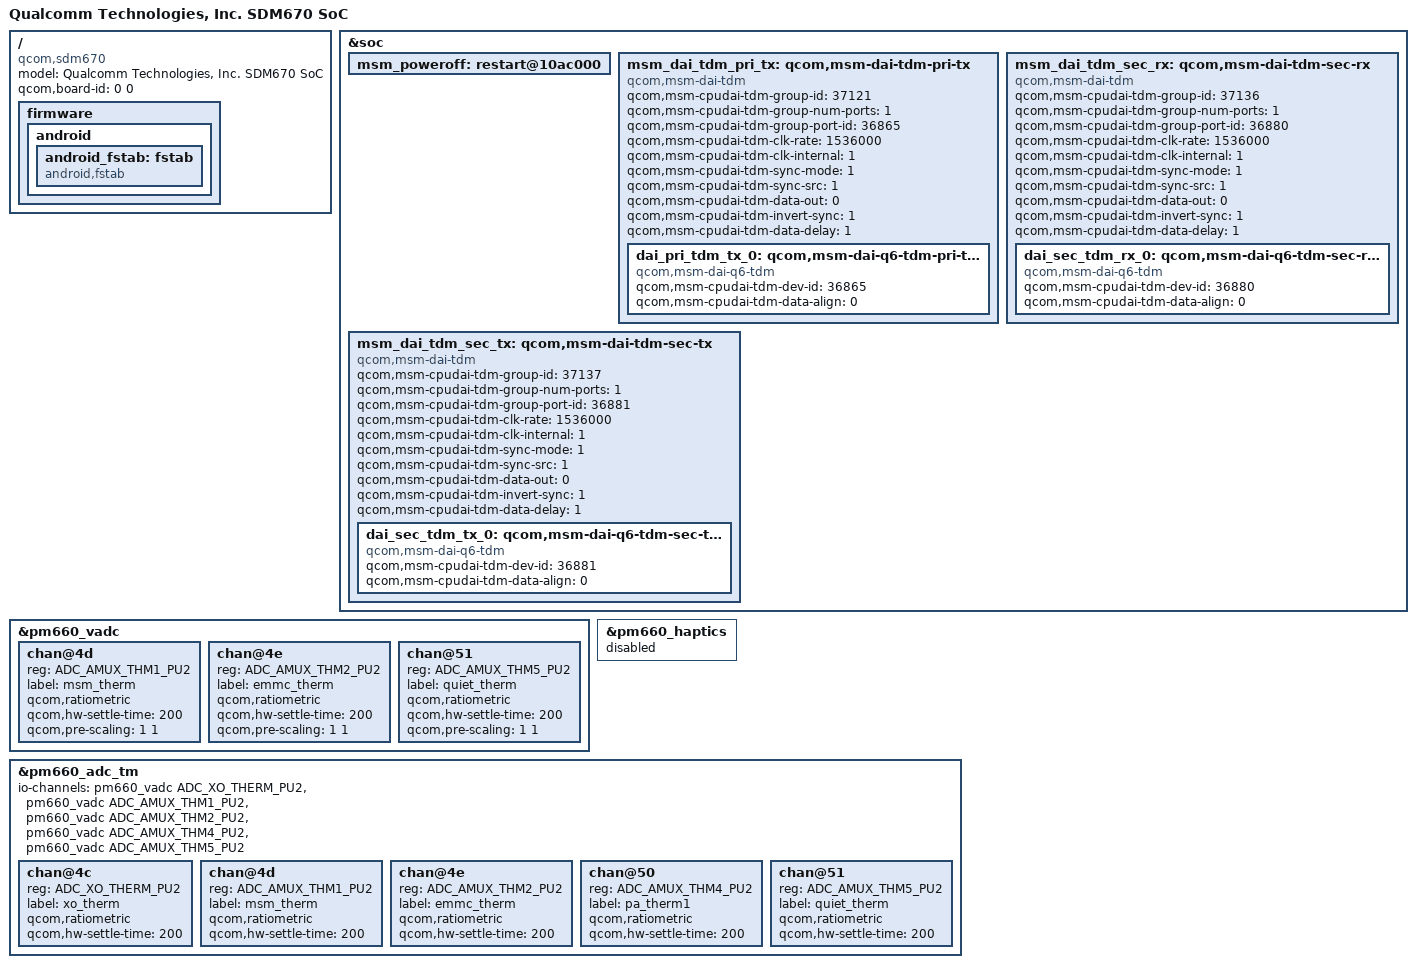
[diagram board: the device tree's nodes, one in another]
// SPDX-License-Identifier: GPL-2.0-only
/*
 * Copyright (C) 2026 The LineageOS Project
 */

/dts-v1/;

#include "sdm670.dtsi"
#include "sdm670-pmic-overlay.dtsi"

/ {
	model = "Qualcomm Technologies, Inc. SDM670 SoC";
	compatible = "qcom,sdm670";
	qcom,board-id = <0 0>;

	firmware {
		android {
			android_fstab: fstab {
				compatible = "android,fstab";
			};
		};
	};
};

&soc {
	/* Labels referenced by the Pixel board overlays */
	msm_poweroff: restart@10ac000 {
	};

	msm_dai_tdm_pri_tx: qcom,msm-dai-tdm-pri-tx {
		compatible = "qcom,msm-dai-tdm";
		qcom,msm-cpudai-tdm-group-id = <37121>;
		qcom,msm-cpudai-tdm-group-num-ports = <1>;
		qcom,msm-cpudai-tdm-group-port-id = <36865>;
		qcom,msm-cpudai-tdm-clk-rate = <1536000>;
		qcom,msm-cpudai-tdm-clk-internal = <1>;
		qcom,msm-cpudai-tdm-sync-mode = <1>;
		qcom,msm-cpudai-tdm-sync-src = <1>;
		qcom,msm-cpudai-tdm-data-out = <0>;
		qcom,msm-cpudai-tdm-invert-sync = <1>;
		qcom,msm-cpudai-tdm-data-delay = <1>;
		dai_pri_tdm_tx_0: qcom,msm-dai-q6-tdm-pri-tx-0 {
			compatible = "qcom,msm-dai-q6-tdm";
			qcom,msm-cpudai-tdm-dev-id = <36865>;
			qcom,msm-cpudai-tdm-data-align = <0>;
		};
	};

	msm_dai_tdm_sec_rx: qcom,msm-dai-tdm-sec-rx {
		compatible = "qcom,msm-dai-tdm";
		qcom,msm-cpudai-tdm-group-id = <37136>;
		qcom,msm-cpudai-tdm-group-num-ports = <1>;
		qcom,msm-cpudai-tdm-group-port-id = <36880>;
		qcom,msm-cpudai-tdm-clk-rate = <1536000>;
		qcom,msm-cpudai-tdm-clk-internal = <1>;
		qcom,msm-cpudai-tdm-sync-mode = <1>;
		qcom,msm-cpudai-tdm-sync-src = <1>;
		qcom,msm-cpudai-tdm-data-out = <0>;
		qcom,msm-cpudai-tdm-invert-sync = <1>;
		qcom,msm-cpudai-tdm-data-delay = <1>;
		dai_sec_tdm_rx_0: qcom,msm-dai-q6-tdm-sec-rx-0 {
			compatible = "qcom,msm-dai-q6-tdm";
			qcom,msm-cpudai-tdm-dev-id = <36880>;
			qcom,msm-cpudai-tdm-data-align = <0>;
		};
	};

	msm_dai_tdm_sec_tx: qcom,msm-dai-tdm-sec-tx {
		compatible = "qcom,msm-dai-tdm";
		qcom,msm-cpudai-tdm-group-id = <37137>;
		qcom,msm-cpudai-tdm-group-num-ports = <1>;
		qcom,msm-cpudai-tdm-group-port-id = <36881>;
		qcom,msm-cpudai-tdm-clk-rate = <1536000>;
		qcom,msm-cpudai-tdm-clk-internal = <1>;
		qcom,msm-cpudai-tdm-sync-mode = <1>;
		qcom,msm-cpudai-tdm-sync-src = <1>;
		qcom,msm-cpudai-tdm-data-out = <0>;
		qcom,msm-cpudai-tdm-invert-sync = <1>;
		qcom,msm-cpudai-tdm-data-delay = <1>;
		dai_sec_tdm_tx_0: qcom,msm-dai-q6-tdm-sec-tx-0 {
			compatible = "qcom,msm-dai-q6-tdm";
			qcom,msm-cpudai-tdm-dev-id = <36881>;
			qcom,msm-cpudai-tdm-data-align = <0>;
		};
	};
};

/* msm-4.9 node names, relabelled by the Pixel overlays */
&pm660_vadc {
	/delete-node/ msm_therm;
	/delete-node/ emmc_therm;
	/delete-node/ quiet_therm;

	chan@4d {
		reg = <ADC_AMUX_THM1_PU2>;
		label = "msm_therm";
		qcom,ratiometric;
		qcom,hw-settle-time = <200>;
		qcom,pre-scaling = <1 1>;
	};

	chan@4e {
		reg = <ADC_AMUX_THM2_PU2>;
		label = "emmc_therm";
		qcom,ratiometric;
		qcom,hw-settle-time = <200>;
		qcom,pre-scaling = <1 1>;
	};

	chan@51 {
		reg = <ADC_AMUX_THM5_PU2>;
		label = "quiet_therm";
		qcom,ratiometric;
		qcom,hw-settle-time = <200>;
		qcom,pre-scaling = <1 1>;
	};
};

/* The overlays disable it by its msm-4.9 node name, qcom,haptics@c000 */
&pm660_haptics {
	status = "disabled";
};

&pm660_adc_tm {
	io-channels = <&pm660_vadc ADC_XO_THERM_PU2>,
		      <&pm660_vadc ADC_AMUX_THM1_PU2>,
		      <&pm660_vadc ADC_AMUX_THM2_PU2>,
		      <&pm660_vadc ADC_AMUX_THM4_PU2>,
		      <&pm660_vadc ADC_AMUX_THM5_PU2>;

	chan@4c {
		reg = <ADC_XO_THERM_PU2>;
		label = "xo_therm";
		qcom,ratiometric;
		qcom,hw-settle-time = <200>;
	};

	chan@4d {
		reg = <ADC_AMUX_THM1_PU2>;
		label = "msm_therm";
		qcom,ratiometric;
		qcom,hw-settle-time = <200>;
	};

	chan@4e {
		reg = <ADC_AMUX_THM2_PU2>;
		label = "emmc_therm";
		qcom,ratiometric;
		qcom,hw-settle-time = <200>;
	};

	chan@50 {
		reg = <ADC_AMUX_THM4_PU2>;
		label = "pa_therm1";
		qcom,ratiometric;
		qcom,hw-settle-time = <200>;
	};

	chan@51 {
		reg = <ADC_AMUX_THM5_PU2>;
		label = "quiet_therm";
		qcom,ratiometric;
		qcom,hw-settle-time = <200>;
	};
};
